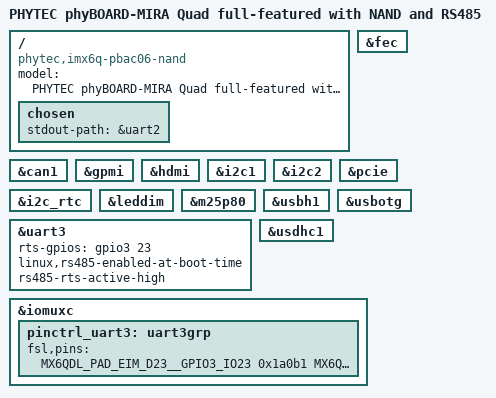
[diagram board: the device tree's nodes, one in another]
// SPDX-License-Identifier: (GPL-2.0+ OR MIT)
/*
 * Copyright (C) 2018 PHYTEC Messtechnik GmbH
 * Author: Christian Hemp <c.hemp@phytec.de>
 */

/dts-v1/;
#include "imx6q.dtsi"
#include "imx6qdl-phytec-phycore-som.dtsi"
#include "imx6qdl-phytec-mira.dtsi"
#include "imx6qdl-phytec-mira-peb-eval-01.dtsi"
#include "imx6qdl-phytec-mira-peb-av-02.dtsi"
#include "imx6qdl-phytec-peb-wlbt-01.dtsi"

/ {
	model = "PHYTEC phyBOARD-MIRA Quad full-featured with NAND and RS485";
	compatible = "phytec,imx6q-pbac06-nand", "phytec,imx6q-pbac06",
		     "phytec,imx6qdl-pcm058", "fsl,imx6q";

	chosen {
		stdout-path = &uart2;
	};
};

&can1 {
	status = "okay";
};

&fec {
	status = "okay";
};

&gpmi {
	status = "okay";
};

&hdmi {
	status = "okay";
};

&i2c1 {
	status = "okay";
};

&i2c2 {
	status = "okay";
};

&i2c_rtc {
	status = "okay";
};

&leddim {
	status = "okay";
};

&m25p80 {
	status = "okay";
};

&pcie {
	status = "okay";
};

&uart3 {
	rts-gpios = <&gpio3 23 GPIO_ACTIVE_HIGH>;
	linux,rs485-enabled-at-boot-time;
	rs485-rts-active-high;
	status = "okay";
};

&usbh1 {
	status = "okay";
};

&usbotg {
	status = "okay";
};

&usdhc1 {
	status = "okay";
};

&iomuxc {
	pinctrl_uart3: uart3grp {
		fsl,pins = <
			MX6QDL_PAD_EIM_D23__GPIO3_IO23		0x1a0b1
			MX6QDL_PAD_EIM_D24__UART3_TX_DATA	0x1b0b1
			MX6QDL_PAD_EIM_D25__UART3_RX_DATA	0x1b0b1
		>;
	};
};
